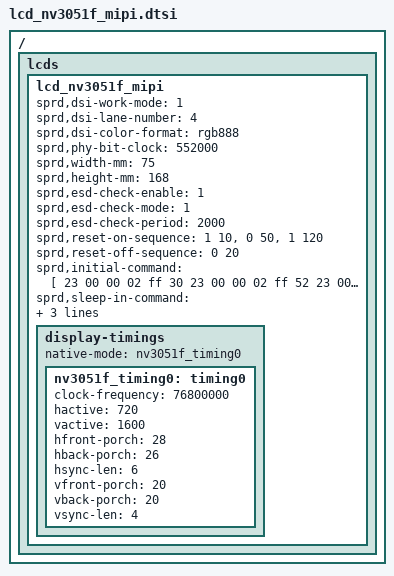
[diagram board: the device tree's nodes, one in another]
/ {
		fragment {
			target-path = "/";
			__overlay__ {
				lcds {
					lcd_nv3051f_mipi: lcd_nv3051f_mipi {
					sprd,dsi-work-mode = <1>;
					sprd,dsi-lane-number = <4>;
					sprd,dsi-color-format = "rgb888";

					sprd,phy-bit-clock = <552000>;	/* kbps */

					sprd,width-mm = <75>;
					sprd,height-mm = <168>;

					sprd,esd-check-enable = <1>;
					sprd,esd-check-mode = <1>;
					sprd,esd-check-period = <2000>;

					/*sprd,use-dcs-write;*/

					sprd,reset-on-sequence = <1 10>, <0 50>, <1 120>;
					sprd,reset-off-sequence = <0 20>;

					sprd,initial-command = [
						23 00 00 02 ff 30
						23 00 00 02 ff 52
						23 00 00 02 ff 01
						23 00 00 02 e3 00
						23 00 00 02 f6 c0
						23 00 00 02 f0 00
						23 00 00 02 25 0A
						23 00 00 02 28 5F
						23 00 00 02 29 06
						23 00 00 02 2A 3F
						23 00 00 02 37 ac
						23 00 00 02 38 97
						23 00 00 02 39 22
						23 00 00 02 44 00
						23 00 00 02 59 fe
						23 00 00 02 5C 4b
						23 00 00 02 49 00
						23 00 00 02 80 20
						23 00 00 02 91 77
						23 00 00 02 92 77
						23 00 00 02 98 CA
						23 00 00 02 99 51
						23 00 00 02 9a C1
						23 00 00 02 9B 59
						23 00 00 02 A0 55
						23 00 00 02 A1 50
						23 00 00 02 A4 9C
						23 00 00 02 A7 02
						23 00 00 02 A8 01
						23 00 00 02 A9 21
						23 00 00 02 AA FC
						23 00 00 02 AB 28
						23 00 00 02 AC 06
						23 00 00 02 AD 06
						23 00 00 02 AE 06
						23 00 00 02 AF 03
						23 00 00 02 B0 08
						23 00 00 02 B1 26
						23 00 00 02 B2 28
						23 00 00 02 B3 28
						23 00 00 02 B4 03
						23 00 00 02 B5 08
						23 00 00 02 B6 26
						23 00 00 02 B7 08
						23 00 00 02 B8 26
						23 00 00 02 FF 30
						23 00 00 02 FF 52
						23 00 00 02 FF 02
						23 00 00 02 B1 12
						23 00 00 02 D1 08
						23 00 00 02 B4 31
						23 00 00 02 D4 27
						23 00 00 02 B2 13
						23 00 00 02 D2 09
						23 00 00 02 B3 31
						23 00 00 02 D3 27
						23 00 00 02 B6 1F
						23 00 00 02 D6 15
						23 00 00 02 B7 3E
						23 00 00 02 D7 34
						23 00 00 02 C1 00
						23 00 00 02 E1 00
						23 00 00 02 B8 0A
						23 00 00 02 D8 00
						23 00 00 02 B9 00
						23 00 00 02 D9 00
						23 00 00 02 BD 19
						23 00 00 02 DD 0F
						23 00 00 02 BC 17
						23 00 00 02 DC 0D
						23 00 00 02 BB 16
						23 00 00 02 DB 0C
						23 00 00 02 BA 17
						23 00 00 02 DA 0D
						23 00 00 02 BE 1D
						23 00 00 02 DE 15
						23 00 00 02 BF 13
						23 00 00 02 DF 0D
						23 00 00 02 C0 1A
						23 00 00 02 E0 14
						23 00 00 02 B5 32
						23 00 00 02 D5 37
						23 00 00 02 B0 02
						23 00 00 02 D0 05
						23 00 00 02 ff 30
						23 00 00 02 ff 52
						23 00 00 02 ff 03
						23 00 00 02 07 05
						23 00 00 02 08 89
						23 00 00 02 09 88
						23 00 00 02 27 02
						23 00 00 02 28 66
						23 00 00 02 29 66
						23 00 00 02 2a 45
						23 00 00 02 2b 46
						23 00 00 02 2c 45
						23 00 00 02 2d 46
						23 00 00 02 30 e0
						23 00 00 02 31 e0
						23 00 00 02 32 e0
						23 00 00 02 33 e0
						23 00 00 02 34 51
						23 00 00 02 35 55
						23 00 00 02 36 55
						23 00 00 02 37 13
						23 00 00 02 40 86
						23 00 00 02 41 85
						23 00 00 02 42 84
						23 00 00 02 43 83
						23 00 00 02 44 66
						23 00 00 02 45 3e
						23 00 00 02 46 3f
						23 00 00 02 47 66
						23 00 00 02 48 40
						23 00 00 02 49 41
						23 00 00 02 50 82
						23 00 00 02 51 81
						23 00 00 02 52 00
						23 00 00 02 53 01
						23 00 00 02 54 66
						23 00 00 02 55 42
						23 00 00 02 56 43
						23 00 00 02 57 66
						23 00 00 02 58 44
						23 00 00 02 59 45
						23 00 00 02 80 0f
						23 00 00 02 81 03
						23 00 00 02 82 0f
						23 00 00 02 83 0e
						23 00 00 02 84 0f
						23 00 00 02 85 0f
						23 00 00 02 86 0f
						23 00 00 02 87 0f
						23 00 00 02 88 07
						23 00 00 02 89 0f
						23 00 00 02 8A 0f
						23 00 00 02 8B 06
						23 00 00 02 8C 05
						23 00 00 02 8D 0f
						23 00 00 02 8E 0f
						23 00 00 02 8F 04
						23 00 00 02 90 00
						23 00 00 02 91 0f
						23 00 00 02 92 0f
						23 00 00 02 93 0f
						23 00 00 02 94 0f
						23 00 00 02 95 0f
						23 00 00 02 96 0f
						23 00 00 02 97 03
						23 00 00 02 98 0f
						23 00 00 02 99 0e
						23 00 00 02 9A 0f
						23 00 00 02 9B 0f
						23 00 00 02 9C 0f
						23 00 00 02 9D 0f
						23 00 00 02 9E 07
						23 00 00 02 9F 0f
						23 00 00 02 A0 0f
						23 00 00 02 A1 06
						23 00 00 02 A2 05
						23 00 00 02 A3 0f
						23 00 00 02 A4 0f
						23 00 00 02 A5 04
						23 00 00 02 A6 00
						23 00 00 02 A7 0f
						23 00 00 02 A8 0f
						23 00 00 02 A9 0f
						23 00 00 02 AA 0f
						23 00 00 02 AB 0f
						23 00 00 02 ff 30
						23 00 00 02 ff 52
						23 00 00 02 ff 00
						23 00 00 02 36 02
						23 00 00 02 53 2C
						23 00 00 02 35 00
						13 C8 00 01 11
						13 14 00 01 29
					];

					sprd,sleep-in-command = [
						13 32 00 01 28
						13 78 00 01 10
					];

					sprd,sleep-out-command = [
						13 78 00 01 11
						13 14 00 01 29
					];

					display-timings {
						native-mode = <&nv3051f_timing0>;
						nv3051f_timing0: timing0 {
							clock-frequency = <76800000>;
							hactive = <720>;
							vactive = <1600>;
							hfront-porch = <28>;
							hback-porch = <26>;
							hsync-len = <6>;
							vfront-porch = <20>;
							vback-porch = <20>;
							vsync-len = <4>;
						};
					};
				};
			};
		};
	};
};


